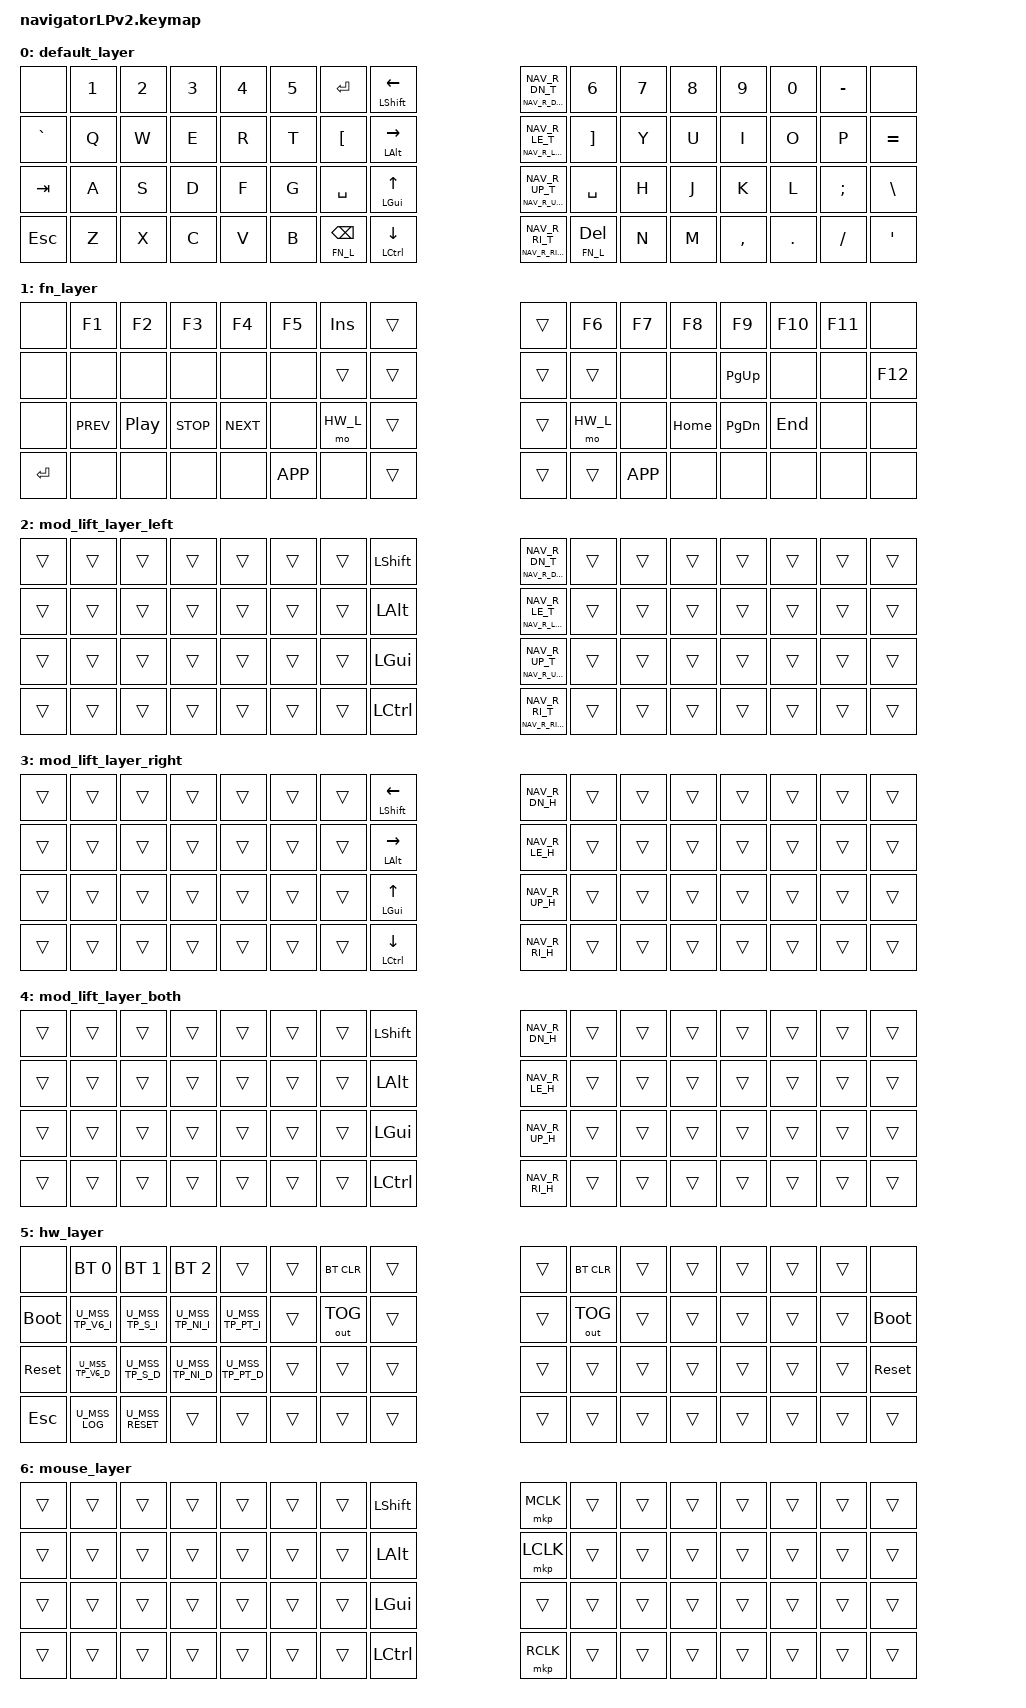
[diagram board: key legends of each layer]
#include <input/processors.dtsi>
#include <behaviors.dtsi>
#include <dt-bindings/zmk/keys.h>
#include <dt-bindings/zmk/bt.h>
#include <dt-bindings/zmk/outputs.h>

#define HAS_MOUSE_TP

#ifdef HAS_MOUSE_TP
    #include <dt-bindings/zmk/mouse.h>
    #include <behaviors/mouse_keys.dtsi>
#endif

#define DEFAULT_LAYER 0
#define FN_L 1
#define MOD_LAYER_L 2
#define MOD_LAYER_R 3
#define MOD_LAYER_B 4
#define HW_L 5
#define MOUSE_TP 6

#ifdef HAS_MOUSE_TP
    #include "mouse.dtsi"
#endif

#define NAV_R_UP_H RGUI
#define NAV_R_UP_T PG_UP
#define NAV_R_DN_H RCTRL
#define NAV_R_DN_T PG_DN
#define NAV_R_LE_H RALT
#define NAV_R_LE_T HOME
#define NAV_R_RI_H RSHFT
#define NAV_R_RI_T END


&lt {
    tapping_term_ms = <150>;
    quick_tap_ms = <300>;
    flavor = "balanced";
};

&mt {
    flavor = "tap-preferred";
};

/ {
    macros {
        mod_liftl: mod_liftl_macro {
            compatible = "zmk,behavior-macro-one-param";
            label = "MOD_EXCUSIVE_LAYER_L";
            #binding-cells = <1>;
            wait-ms = <0>;
            bindings
                = <&macro_press &mo MOD_LAYER_L>
                , <&macro_param_1to1 &macro_press &kp MACRO_PLACEHOLDER>
                , <&macro_pause_for_release>
                , <&macro_param_1to1 &macro_release &kp MACRO_PLACEHOLDER>
                , <&macro_release &mo MOD_LAYER_L>;
        };

        mod_liftr: mod_liftr_macro {
            compatible = "zmk,behavior-macro-one-param";
            label = "MOD_EXCUSIVE_LAYER_R";
            #binding-cells = <1>;
            wait-ms = <0>;
            bindings
                = <&macro_press &mo MOD_LAYER_R>
                , <&macro_param_1to1 &macro_press &kp MACRO_PLACEHOLDER>
                , <&macro_pause_for_release>
                , <&macro_param_1to1 &macro_release &kp MACRO_PLACEHOLDER>
                , <&macro_release &mo MOD_LAYER_R>;
        };
    };
    
    conditional_layers {
        compatible = "zmk,conditional-layers";
        tri_layer {
            if-layers = <2 3>;
            then-layer = <4>;
        };
    };

    behaviors {
        th_liftl: th_liftl_taphold {
            compatible = "zmk,behavior-hold-tap";
            label = "LIFT_MOD_L";
            #binding-cells = <2>;
            tapping_term_ms = <300>;
            flavor = "hold-preferred";
            bindings = <&mod_liftl>, <&kp>;
            quick_tap_ms = <500>;
        };

        th_liftr: th_liftr_taphold {
            compatible = "zmk,behavior-hold-tap";
            label = "LIFT_MOD_R";
            #binding-cells = <2>;
            tapping_term_ms = <300>;
            flavor = "hold-preferred";
            bindings = <&mod_liftr>, <&kp>;
            quick_tap_ms = <500>;
        };
    };

    keymap {
        compatible = "zmk,keymap";

        default_layer {
            bindings = <
    &none      &kp N1  &kp N2  &kp N3  &kp N4  &kp N5  &kp ENTER      &th_liftl LSHFT LEFT    &th_liftr NAV_R_DN_H NAV_R_DN_T   &kp N6        &kp N7  &kp N8  &kp N9     &kp N0   &kp MINUS  &none
    &kp GRAVE  &kp Q   &kp W   &kp E   &kp R   &kp T   &kp LBKT       &th_liftl LALT RIGHT    &th_liftr NAV_R_LE_H NAV_R_LE_T   &kp RBKT      &kp Y   &kp U   &kp I      &kp O    &kp P      &kp EQUAL
    &kp TAB    &kp A   &kp S   &kp D   &kp F   &kp G   &kp SPACE      &th_liftl LGUI UP       &th_liftr NAV_R_UP_H NAV_R_UP_T   &kp SPACE     &kp H   &kp J   &kp K      &kp L    &kp SEMI   &kp BSLH
    &kp ESC    &kp Z   &kp X   &kp C   &kp V   &kp B   &lt FN_L BSPC  &th_liftl LCTRL DOWN    &th_liftr NAV_R_RI_H NAV_R_RI_T   &lt FN_L DEL  &kp N   &kp M   &kp COMMA  &kp DOT  &kp FSLH   &kp SQT
            >;
        };

        fn_layer {
            bindings = <
    &none      &kp F1      &kp F2    &kp F3      &kp F4      &kp F5      &kp INS   &trans    &trans  &kp F6    &kp F7     &kp F8    &kp F9     &kp F10  &kp F11   &none
    &none      &none       &none     &none       &none       &none       &trans    &trans    &trans  &trans    &none      &none     &kp PG_UP  &none    &none     &kp F12
    &none      &kp C_PREV  &kp C_PP  &kp C_STOP  &kp C_NEXT  &none       &mo HW_L  &trans    &trans  &mo HW_L  &none      &kp HOME  &kp PG_DN  &kp END  &none     &none
    &kp ENTER  &none       &none     &none       &none       &kp K_APP   &none     &trans    &trans  &trans    &kp K_APP  &none     &none      &none    &none     &none
            >;
        };

        mod_lift_layer_left {
            bindings = <
    &trans     &trans  &trans  &trans  &trans  &trans  &trans         &kp LSHFT               &th_liftr NAV_R_DN_H NAV_R_DN_T  &trans        &trans  &trans  &trans     &trans   &trans     &trans
    &trans     &trans  &trans  &trans  &trans  &trans  &trans         &kp LALT                &th_liftr NAV_R_LE_H NAV_R_LE_T  &trans        &trans  &trans  &trans     &trans   &trans     &trans
    &trans     &trans  &trans  &trans  &trans  &trans  &trans         &kp LGUI                &th_liftr NAV_R_UP_H NAV_R_UP_T  &trans        &trans  &trans  &trans     &trans   &trans     &trans
    &trans      &trans  &trans  &trans  &trans  &trans  &trans         &kp LCTRL               &th_liftr NAV_R_RI_H NAV_R_RI_T  &trans        &trans  &trans  &trans     &trans   &trans     &trans
            >;
        };

        mod_lift_layer_right {
            bindings = <
    &trans     &trans  &trans  &trans  &trans  &trans  &trans         &th_liftl LSHFT LEFT    &kp NAV_R_DN_H  &trans        &trans  &trans  &trans     &trans   &trans     &trans
    &trans     &trans  &trans  &trans  &trans  &trans  &trans         &th_liftl LALT RIGHT    &kp NAV_R_LE_H  &trans        &trans  &trans  &trans     &trans   &trans     &trans
    &trans     &trans  &trans  &trans  &trans  &trans  &trans         &th_liftl LGUI UP       &kp NAV_R_UP_H  &trans        &trans  &trans  &trans     &trans   &trans     &trans
    &trans      &trans  &trans  &trans  &trans  &trans  &trans         &th_liftl LCTRL DOWN    &kp NAV_R_RI_H  &trans        &trans  &trans  &trans     &trans   &trans     &trans
            >;
        };

        mod_lift_layer_both {
            bindings = <
    &trans     &trans  &trans  &trans  &trans  &trans  &trans         &kp LSHFT               &kp NAV_R_DN_H  &trans        &trans  &trans  &trans     &trans   &trans     &trans
    &trans     &trans  &trans  &trans  &trans  &trans  &trans         &kp LALT                &kp NAV_R_LE_H  &trans        &trans  &trans  &trans     &trans   &trans     &trans
    &trans     &trans  &trans  &trans  &trans  &trans  &trans         &kp LGUI                &kp NAV_R_UP_H  &trans        &trans  &trans  &trans     &trans   &trans     &trans
    &trans      &trans  &trans  &trans  &trans  &trans  &trans         &kp LCTRL               &kp NAV_R_RI_H  &trans        &trans  &trans  &trans     &trans   &trans     &trans
            >;
        };

        hw_layer {
            bindings = <
    &none        &bt BT_SEL 0   &bt BT_SEL 1  &bt BT_SEL 2  &trans         &trans  &bt BT_CLR    &trans    &trans  &bt BT_CLR    &trans  &trans  &trans  &trans  &trans  &none
    &bootloader  U_MSS_TP_V6_I  U_MSS_TP_S_I  U_MSS_TP_NI_I U_MSS_TP_PT_I  &trans  &out OUT_TOG  &trans    &trans  &out OUT_TOG  &trans  &trans  &trans  &trans  &trans  &bootloader
    &sys_reset   U_MSS_TP_V6_D  U_MSS_TP_S_D  U_MSS_TP_NI_D U_MSS_TP_PT_D  &trans  &trans        &trans    &trans  &trans        &trans  &trans  &trans  &trans  &trans  &sys_reset
    &kp ESC      U_MSS_LOG      U_MSS_RESET   &trans        &trans         &trans  &trans        &trans    &trans  &trans        &trans  &trans  &trans  &trans  &trans  &trans
            >;
        };

#ifdef HAS_MOUSE_TP
        mouse_layer {
            bindings = <
    &trans     &trans  &trans  &trans  &trans  &trans  &trans         &kp LSHFT               &mkp MCLK  &trans        &trans  &trans  &trans     &trans   &trans     &trans
    &trans     &trans  &trans  &trans  &trans  &trans  &trans         &kp LALT                &mkp LCLK  &trans        &trans  &trans  &trans     &trans   &trans     &trans
    &trans     &trans  &trans  &trans  &trans  &trans  &trans         &kp LGUI                &trans     &trans        &trans  &trans  &trans     &trans   &trans     &trans
    &trans     &trans  &trans  &trans  &trans  &trans  &trans         &kp LCTRL               &mkp RCLK  &trans        &trans  &trans  &trans     &trans   &trans     &trans
            >;
        };
#endif
    };
};
